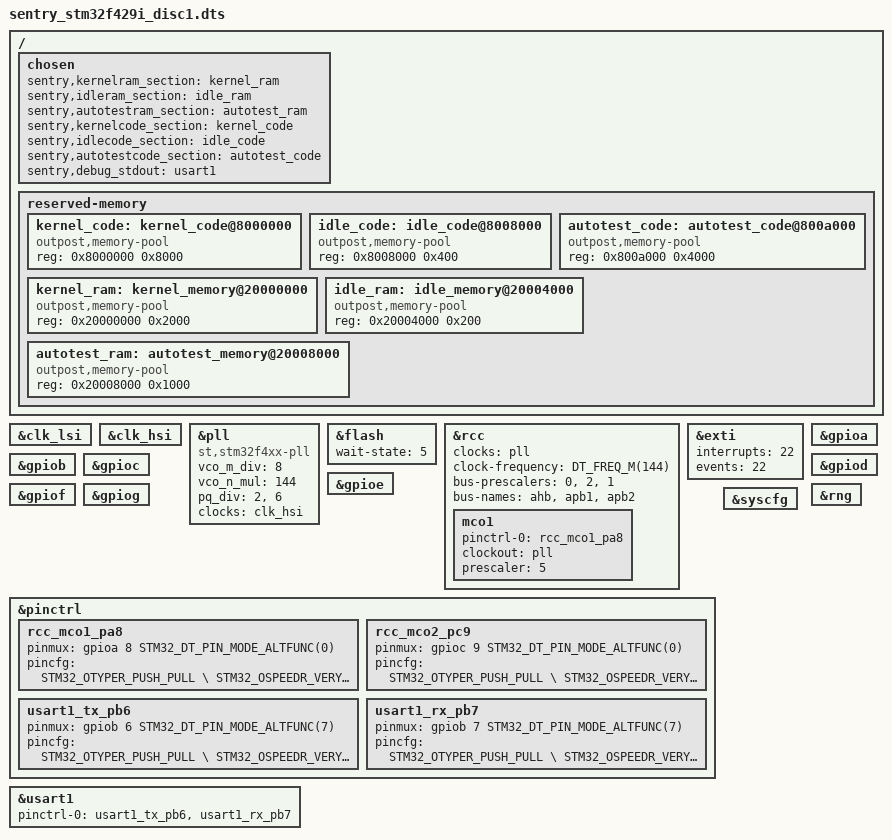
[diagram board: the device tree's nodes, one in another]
/*
 * Copyright (c) 2023,Ledger SAS
 *
 * SPDX-License-Identifier: Apache-2.0
 */

/dts-v1/;

#include <st/f4/stm32f429Xi.dtsi>
#include <dt-bindings/pinctrl/stm32-pinctrl.h>

/{
	chosen {
		sentry,kernelram_section = <&kernel_ram>;
		sentry,idleram_section = <&idle_ram>;
		sentry,autotestram_section = <&autotest_ram>;
		sentry,kernelcode_section = <&kernel_code>;
		sentry,idlecode_section = <&idle_code>;
		sentry,autotestcode_section = <&autotest_code>;
		sentry,debug_stdout = <&usart1>;
	};

	reserved-memory {
		#address-cells = <1>;
		#size-cells = <1>;

		kernel_code: kernel_code@8000000 {
        	reg = <0x8000000 0x8000>;
			compatible = "outpost,memory-pool";
    	};
		idle_code: idle_code@8008000 {
        	reg = <0x8008000 0x400>;
			compatible = "outpost,memory-pool";
    	};
		autotest_code: autotest_code@800a000 {
			reg = <0x800a000 0x4000>;
			compatible = "outpost,memory-pool";
		};

		kernel_ram: kernel_memory@20000000 {
        	reg = <0x20000000 0x2000>;
			compatible = "outpost,memory-pool";
    	};
    	idle_ram: idle_memory@20004000 {
        	reg = <0x20004000 0x200>;
			compatible = "outpost,memory-pool";
    	};
		autotest_ram: autotest_memory@20008000 {
        	reg = <0x20008000 0x1000>;
			compatible = "outpost,memory-pool";
    	};
	};
};


&clk_lsi {
	status = "okay";
};

&clk_hsi {
	status = "okay";
};

/* TODO: checks binding, this is our very own property for plls */
&pll {
	vco_m_div = <8>;
	vco_n_mul = <144>;
	pq_div = <2>, <6>;
	clocks = <&clk_hsi>;
	status = "okay";
	compatible = "st,stm32f4xx-pll";
};

&flash {
	wait-state = <5>; /* According to voltage supply and sysclock */
	status = "okay";
};

&rcc {
	clocks = <&pll>;
	clock-frequency = <DT_FREQ_M(144)>;
	bus-prescalers = <0>, <2>, <1>;
	bus-names = "ahb", "apb1", "apb2";
	status = "okay";

	mco1 {
		pinctrl-0 = <&rcc_mco1_pa8>;
		clockout = <&pll>; /* XXX use reg value from svd */
		prescaler = <5>;
		status = "okay";
	};
};

&exti {
	interrupts = <22>;
	events = <22>;
	status = "okay";
};

&gpioa {
	status = "okay";
};

&gpiob {
	status = "okay";
};

&gpioc {
	status = "okay";
};

&gpiod {
	status = "okay";
};

&gpioe {
	status = "okay";
};

&gpiof {
	status = "okay";
};

&gpiog {
	status = "okay";
};

&pinctrl {
	rcc_mco1_pa8: rcc_mco1_pa8  {
		pinmux = <&gpioa 8 STM32_DT_PIN_MODE_ALTFUNC(0)>;
		pincfg = <STM32_OTYPER_PUSH_PULL \
				  STM32_OSPEEDR_VERY_HIGH_SPEED \
				  STM32_PUPDR_NO_PULL>;
	};

	rcc_mco2_pc9: rcc_mco2_pc9 {
		pinmux = <&gpioc 9 STM32_DT_PIN_MODE_ALTFUNC(0)>;
		pincfg = <STM32_OTYPER_PUSH_PULL \
				  STM32_OSPEEDR_VERY_HIGH_SPEED \
				  STM32_PUPDR_NO_PULL>;
	};

	usart1_tx_pb6: usart1_tx_pb6  {
		pinmux = <&gpiob 6 STM32_DT_PIN_MODE_ALTFUNC(7)>;
		pincfg = <STM32_OTYPER_PUSH_PULL \
				  STM32_OSPEEDR_VERY_HIGH_SPEED \
				  STM32_PUPDR_NO_PULL>;
	};

	usart1_rx_pb7: usart1_rx_pb7  {
		pinmux = <&gpiob 7 STM32_DT_PIN_MODE_ALTFUNC(7)>;
		pincfg = <STM32_OTYPER_PUSH_PULL \
				  STM32_OSPEEDR_VERY_HIGH_SPEED \
				  STM32_PUPDR_NO_PULL>;
	};
};

&usart1 {
    status = "okay";
	pinctrl-0 = <&usart1_tx_pb6>, <&usart1_rx_pb7>;
};

&rng {
	status = "okay";
};

&syscfg {
	status = "okay";
};
